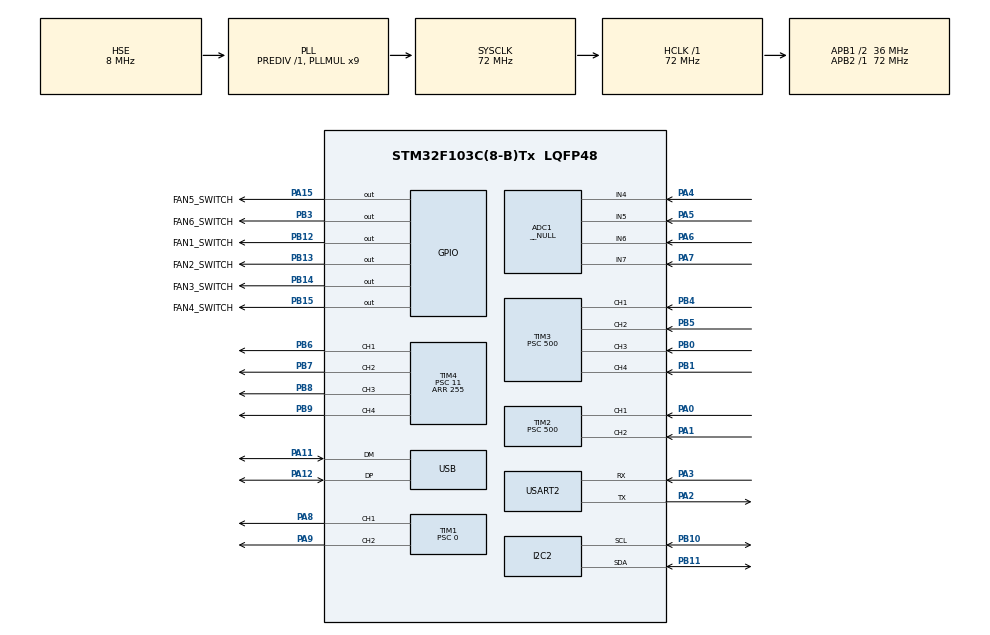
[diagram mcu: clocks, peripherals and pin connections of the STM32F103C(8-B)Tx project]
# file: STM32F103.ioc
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ADC1.Channel-10\#ChannelRegularConversion=ADC_CHANNEL_6
ADC1.Channel-11\#ChannelRegularConversion=ADC_CHANNEL_7
ADC1.Channel-4\#ChannelRegularConversion=ADC_CHANNEL_4
ADC1.Channel-9\#ChannelRegularConversion=ADC_CHANNEL_5
ADC1.ContinuousConvMode=ENABLE
ADC1.DataAlign=ADC_DATAALIGN_RIGHT
ADC1.EnableInjectedConversion=DISABLE
ADC1.Mode=__NULL
ADC1.NbrOfConversion=4
ADC1.NbrOfConversionFlag=1
ADC1.Rank-10\#ChannelRegularConversion=3
ADC1.Rank-11\#ChannelRegularConversion=4
ADC1.Rank-4\#ChannelRegularConversion=1
ADC1.Rank-9\#ChannelRegularConversion=2
ADC1.SamplingTime-10\#ChannelRegularConversion=ADC_SAMPLETIME_1CYCLE_5
ADC1.SamplingTime-11\#ChannelRegularConversion=ADC_SAMPLETIME_1CYCLE_5
ADC1.SamplingTime-4\#ChannelRegularConversion=ADC_SAMPLETIME_239CYCLES_5
ADC1.SamplingTime-9\#ChannelRegularConversion=ADC_SAMPLETIME_239CYCLES_5
ADC1.master=1
Dma.ADC1.0.Direction=DMA_PERIPH_TO_MEMORY
Dma.ADC1.0.Instance=DMA1_Channel1
Dma.ADC1.0.MemDataAlignment=DMA_MDATAALIGN_HALFWORD
Dma.ADC1.0.MemInc=DMA_MINC_ENABLE
Dma.ADC1.0.Mode=DMA_CIRCULAR
Dma.ADC1.0.PeriphDataAlignment=DMA_PDATAALIGN_HALFWORD
Dma.ADC1.0.PeriphInc=DMA_PINC_DISABLE
Dma.ADC1.0.Priority=DMA_PRIORITY_LOW
Dma.Request0=ADC1
Mcu.Family=STM32F1
Mcu.Name=STM32F103C(8-B)Tx
Mcu.Package=LQFP48
NVIC.ADC1_2_IRQn=true\:0\:0\:false\:false\:true\:true\:true
NVIC.DMA1_Channel1_IRQn=true\:0\:0\:false\:false\:true\:false\:true
NVIC.PriorityGroup=NVIC_PRIORITYGROUP_4
NVIC.TIM1_CC_IRQn=true\:0\:0\:false\:false\:true\:true\:true
NVIC.TIM2_IRQn=true\:0\:0\:false\:false\:true\:true\:true
NVIC.TIM3_IRQn=true\:0\:0\:false\:false\:true\:true\:true
NVIC.TIM4_IRQn=true\:0\:0\:false\:false\:true\:true\:true
NVIC.USB_LP_CAN1_RX0_IRQn=true\:0\:0\:false\:false\:true\:false\:true
PA0-WKUP.GPIO_PuPd=GPIO_PULLUP
PA0-WKUP.Signal=S_TIM2_CH1_ETR
PA1.GPIO_PuPd=GPIO_PULLUP
PA1.Signal=S_TIM2_CH2
PA10.Signal=S_TIM1_CH3
PA11.Mode=Device
PA11.Signal=USB_DM
PA12.Mode=Device
PA12.Signal=USB_DP
PA13.Mode=Serial_Wire
PA13.Signal=SYS_JTMS-SWDIO
PA14.Mode=Serial_Wire
PA14.Signal=SYS_JTCK-SWCLK
PA15.GPIO_Label=FAN5_SWITCH
PA15.GPIO_PuPd=GPIO_NOPULL
PA15.Signal=GPIO_Output
PA2.Mode=Asynchronous
PA2.Signal=USART2_TX
PA3.Mode=Asynchronous
PA3.Signal=USART2_RX
PA4.Signal=ADCx_IN4
PA5.Signal=ADCx_IN5
PA6.Signal=ADCx_IN6
PA7.Signal=ADCx_IN7
PA8.Signal=S_TIM1_CH1
PA9.Signal=S_TIM1_CH2
PB0.GPIO_PuPd=GPIO_PULLUP
PB0.Signal=S_TIM3_CH3
PB1.GPIO_PuPd=GPIO_PULLUP
PB1.Signal=S_TIM3_CH4
PB10.Mode=I2C
PB10.Signal=I2C2_SCL
PB11.Mode=I2C
PB11.Signal=I2C2_SDA
PB12.GPIO_Label=FAN1_SWITCH
PB12.GPIO_PuPd=GPIO_NOPULL
PB12.Signal=GPIO_Output
PB13.GPIO_Label=FAN2_SWITCH
PB13.GPIO_PuPd=GPIO_NOPULL
PB13.Signal=GPIO_Output
PB14.GPIO_Label=FAN3_SWITCH
PB14.GPIO_PuPd=GPIO_NOPULL
PB14.Signal=GPIO_Output
PB15.GPIO_Label=FAN4_SWITCH
PB15.GPIO_PuPd=GPIO_NOPULL
PB15.Signal=GPIO_Output
PB3.GPIO_Label=FAN6_SWITCH
PB3.GPIO_PuPd=GPIO_NOPULL
PB3.Signal=GPIO_Output
PB4.GPIO_PuPd=GPIO_PULLUP
PB4.Signal=S_TIM3_CH1
PB5.GPIO_PuPd=GPIO_PULLUP
PB5.Signal=S_TIM3_CH2
PB6.Signal=S_TIM4_CH1
PB7.Signal=S_TIM4_CH2
PB8.Signal=S_TIM4_CH3
PB9.Signal=S_TIM4_CH4
PC14-OSC32_IN.Mode=LSE-External-Oscillator
PC14-OSC32_IN.Signal=RCC_OSC32_IN
PC15-OSC32_OUT.Mode=LSE-External-Oscillator
PC15-OSC32_OUT.Signal=RCC_OSC32_OUT
PD0-OSC_IN.Mode=HSE-External-Oscillator
PD0-OSC_IN.Signal=RCC_OSC_IN
PD1-OSC_OUT.Mode=HSE-External-Oscillator
PD1-OSC_OUT.Signal=RCC_OSC_OUT
ProjectManager.HeapSize=0x200
ProjectManager.StackSize=0x400
ProjectManager.TargetToolchain=STM32CubeIDE
RCC.ADCPresc=RCC_ADCPCLK2_DIV6
RCC.AHBFreq_Value=72000000
RCC.APB1CLKDivider=RCC_HCLK_DIV2
RCC.APB1Freq_Value=36000000
RCC.APB1TimFreq_Value=72000000
RCC.APB2Freq_Value=72000000
RCC.APB2TimFreq_Value=72000000
RCC.HCLKFreq_Value=72000000
RCC.PLLMUL=RCC_PLL_MUL9
RCC.SYSCLKFreq_VALUE=72000000
RCC.SYSCLKSource=RCC_SYSCLKSOURCE_PLLCLK
RCC.USBFreq_Value=48000000
RCC.USBPrescaler=RCC_USBCLKSOURCE_PLL_DIV1_5
SH.ADCx_IN4.0=ADC1_IN4,IN4
SH.ADCx_IN5.0=ADC1_IN5,IN5
SH.ADCx_IN6.0=ADC1_IN6,IN6
SH.ADCx_IN7.0=ADC1_IN7,IN7
SH.S_TIM1_CH1.0=TIM1_CH1,PWM Generation1 CH1
SH.S_TIM1_CH2.0=TIM1_CH2,PWM Generation2 CH2
SH.S_TIM1_CH3.0=TIM1_CH3
SH.S_TIM2_CH1_ETR.0=TIM2_CH1,Input_Capture1_from_TI1
SH.S_TIM2_CH2.0=TIM2_CH2,Input_Capture2_from_TI2
SH.S_TIM3_CH1.0=TIM3_CH1,Input_Capture1_from_TI1
SH.S_TIM3_CH2.0=TIM3_CH2,Input_Capture2_from_TI2
SH.S_TIM3_CH3.0=TIM3_CH3,Input_Capture3_from_TI3
SH.S_TIM3_CH4.0=TIM3_CH4,Input_Capture4_from_TI4
SH.S_TIM4_CH1.0=TIM4_CH1,PWM Generation1 CH1
SH.S_TIM4_CH2.0=TIM4_CH2,PWM Generation2 CH2
SH.S_TIM4_CH3.0=TIM4_CH3,PWM Generation3 CH3
SH.S_TIM4_CH4.0=TIM4_CH4,PWM Generation4 CH4
TIM1.Channel-PWM\ Generation1\ CH1=TIM_CHANNEL_1
TIM1.Channel-PWM\ Generation2\ CH2=TIM_CHANNEL_2
TIM1.Period=65535
TIM1.Prescaler=0
TIM2.Channel-Input_Capture1_from_TI1=TIM_CHANNEL_1
TIM2.Channel-Input_Capture2_from_TI2=TIM_CHANNEL_2
TIM2.Prescaler=500
TIM3.Channel-Input_Capture1_from_TI1=TIM_CHANNEL_1
TIM3.Channel-Input_Capture2_from_TI2=TIM_CHANNEL_2
TIM3.Channel-Input_Capture3_from_TI3=TIM_CHANNEL_3
TIM3.Channel-Input_Capture4_from_TI4=TIM_CHANNEL_4
TIM3.Prescaler=500
TIM4.Channel-PWM\ Generation1\ CH1=TIM_CHANNEL_1
TIM4.Channel-PWM\ Generation2\ CH2=TIM_CHANNEL_2
TIM4.Channel-PWM\ Generation3\ CH3=TIM_CHANNEL_3
TIM4.Channel-PWM\ Generation4\ CH4=TIM_CHANNEL_4
TIM4.Period=255
TIM4.Prescaler=11
TIM4.Pulse-PWM\ Generation4\ CH4=0
USART2.VirtualMode=VM_ASYNC
USB_DEVICE.CLASS_NAME_FS=CUSTOM_HID
USB_DEVICE.CUSTOM_HID_FS_BINTERVAL=0x01
USB_DEVICE.MANUFACTURER_STRING=OpenFanHub
USB_DEVICE.PID_CUSTOMHID_FS=0x0c10
USB_DEVICE.PRODUCT_STRING_CUSTOMHID_FS=OpenFanHub v0.1
USB_DEVICE.USBD_CUSTOMHID_OUTREPORT_BUF_SIZE=64
USB_DEVICE.USBD_CUSTOM_HID_REPORT_DESC_SIZE=37
USB_DEVICE.USBD_DEBUG_LEVEL=0
USB_DEVICE.VID=0x1b1c
USB_DEVICE.VirtualMode=CustomHid
USB_DEVICE.VirtualModeFS=Custom_Hid_FS
VP_USB_DEVICE_VS_USB_DEVICE_CUSTOM_HID_FS.Mode=CUSTOM_HID_FS
board=custom

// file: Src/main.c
/* USER CODE BEGIN Header */
/**
  ******************************************************************************
  * @file           : main.c
  * @brief          : Main program body
  ******************************************************************************
  * @attention
  *
  * Copyright (c) 2021 STMicroelectronics.
  * All rights reserved.
  *
  * This software is licensed under terms that can be found in the LICENSE file
  * in the root directory of this software component.
  * If no LICENSE file comes with this software, it is provided AS-IS.
  *
  ******************************************************************************
  */
/* USER CODE END Header */
#include "main.h"
#include "adc.h"
#include "dma.h"
#include "i2c.h"
#include "tim.h"
#include "usart.h"
#include "usb_device.h"
#include "gpio.h"

void SystemClock_Config(void);

/* USER CODE BEGIN 0 */
#ifdef USE_CUBEMX_MAIN
/* USER CODE END 0 */

int main(void)
{
  /* USER CODE BEGIN 1 */
#else
void init_cubemx() {
#endif

  /* USER CODE END 1 */

  /* MCU Configuration--------------------------------------------------------*/

  /* Reset of all peripherals, Initializes the Flash interface and the Systick. */
  HAL_Init();

  /* Configure the system clock */
  SystemClock_Config();

  /* Initialize all configured peripherals */
  MX_GPIO_Init();
  MX_TIM1_Init();
  MX_TIM2_Init();
  MX_TIM3_Init();
  MX_TIM4_Init();
  MX_USB_DEVICE_Init();
  MX_ADC1_Init();
  MX_I2C2_Init();
  MX_DMA_Init();
  MX_USART2_UART_Init();

  /* Infinite loop */

}

void SystemClock_Config(void)
{
  RCC_OscInitTypeDef RCC_OscInitStruct = {0};
  RCC_ClkInitTypeDef RCC_ClkInitStruct = {0};
  RCC_PeriphCLKInitTypeDef PeriphClkInit = {0};

  /** Initializes the RCC Oscillators according to the specified parameters
  * in the RCC_OscInitTypeDef structure.
  */
  RCC_OscInitStruct.OscillatorType = RCC_OSCILLATORTYPE_HSE;
  RCC_OscInitStruct.HSEState = RCC_HSE_ON;
  RCC_OscInitStruct.HSEPredivValue = RCC_HSE_PREDIV_DIV1;
  RCC_OscInitStruct.HSIState = RCC_HSI_ON;
  RCC_OscInitStruct.PLL.PLLState = RCC_PLL_ON;
  RCC_OscInitStruct.PLL.PLLSource = RCC_PLLSOURCE_HSE;
  RCC_OscInitStruct.PLL.PLLMUL = RCC_PLL_MUL9;
  if (HAL_RCC_OscConfig(&RCC_OscInitStruct) != HAL_OK)
  {
    Error_Handler();
  }
  /** Initializes the CPU, AHB and APB buses clocks
  */
  RCC_ClkInitStruct.ClockType = RCC_CLOCKTYPE_HCLK|RCC_CLOCKTYPE_SYSCLK
                              |RCC_CLOCKTYPE_PCLK1|RCC_CLOCKTYPE_PCLK2;
  RCC_ClkInitStruct.SYSCLKSource = RCC_SYSCLKSOURCE_PLLCLK;
  RCC_ClkInitStruct.AHBCLKDivider = RCC_SYSCLK_DIV1;
  RCC_ClkInitStruct.APB1CLKDivider = RCC_HCLK_DIV2;
  RCC_ClkInitStruct.APB2CLKDivider = RCC_HCLK_DIV1;

  if (HAL_RCC_ClockConfig(&RCC_ClkInitStruct, FLASH_LATENCY_2) != HAL_OK)
  {
    Error_Handler();
  }
  PeriphClkInit.PeriphClockSelection = RCC_PERIPHCLK_ADC|RCC_PERIPHCLK_USB;
  PeriphClkInit.AdcClockSelection = RCC_ADCPCLK2_DIV6;
  PeriphClkInit.UsbClockSelection = RCC_USBCLKSOURCE_PLL_DIV1_5;
  if (HAL_RCCEx_PeriphCLKConfig(&PeriphClkInit) != HAL_OK)
  {
    Error_Handler();
  }
}

void Error_Handler(void)
{
  __disable_irq();
  while (1)
  {
  }
}
